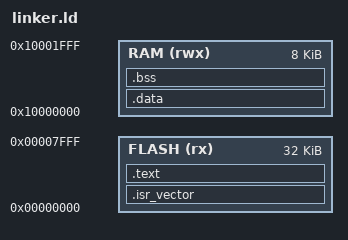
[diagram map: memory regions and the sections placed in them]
ENTRY(Reset_Handler)

MEMORY
{
  FLASH (rx) : ORIGIN = 0x00000000, LENGTH = 32K
  RAM (rwx)  : ORIGIN = 0x10000000, LENGTH = 8K
}

_estack = ORIGIN(RAM) + LENGTH(RAM);

SECTIONS
{
  .isr_vector :
  {
    KEEP(*(.isr_vector))
  } > FLASH

  .text : 
  {
    *(.text*)
    *(.rodata*)
  } > FLASH

  .data : AT (ADDR(.text) + SIZEOF(.text))
  {
    _sidata = LOADADDR(.data);
    _sdata = .;
    *(.data*)
    _edata = .;
  } > RAM

  .bss :
  {
    _sbss = .;
    *(.bss*)
    *(COMMON)
    _ebss = .;
  } > RAM
}

